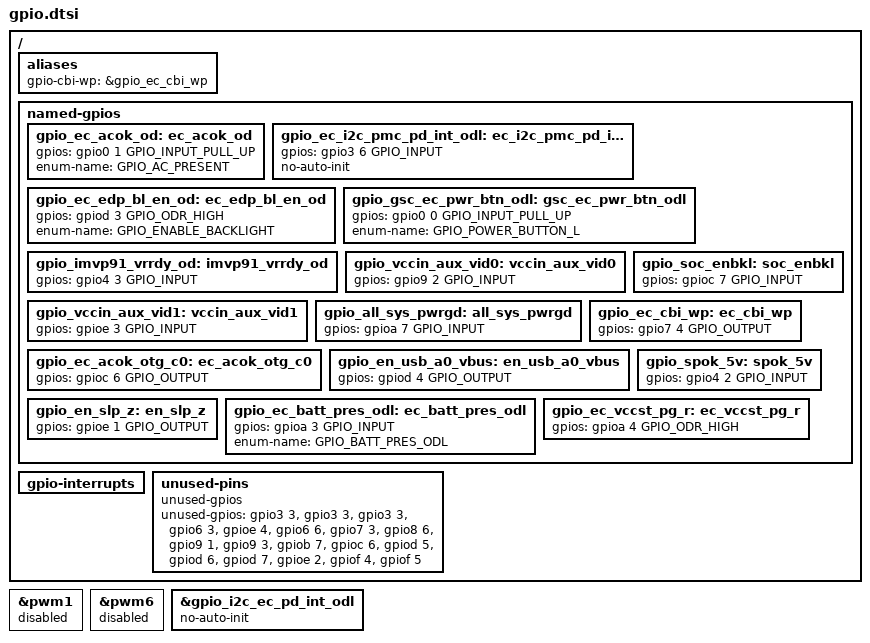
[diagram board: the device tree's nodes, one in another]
/* Copyright 2024 The ChromiumOS Authors
 * Use of this source code is governed by a BSD-style license that can be
 * found in the LICENSE file.
 */

 / {
	aliases {
		gpio-cbi-wp = &gpio_ec_cbi_wp;
	};

	named-gpios {
		/delete-node/ acok_od;
		/delete-node/ amp_mute_l;
		/delete-node/ charger_vap_otg_en;
		/delete-node/ ec_pmc_pd_int_odl;
		/delete-node/ ec_pwr_btn_odl;
		/delete-node/ ec_tris_l;
		/delete-node/ en_kb_bl;
		/delete-node/ en_pp5000_pen_x;
		/delete-node/ gsc_ec_pwr_btn_odl;
		/delete-node/ imvp91_vrrdy_r_od;
		/delete-node/ pdc_rst;
		/delete-node/ pen_detect_odl;
		/delete-node/ vccin_aux_r_vid0;
		/delete-node/ vccin_aux_r_vid1;
		/delete-node/ all_sys_pwrgd;
		/delete-node/ volup_btn_odl;
		/delete-node/ voldn_btn_odl;
		/delete-node/ en_pp5000_vbus;
		/delete-node/ ec_soc_vccst_pwrgd_od;
		/delete-node/ pg_pp5000_z1_od;

		gpio_ec_acok_od: ec_acok_od {
			gpios = <&gpio0 1 GPIO_INPUT_PULL_UP>;
			enum-name = "GPIO_AC_PRESENT";
		};
		gpio_ec_i2c_pmc_pd_int_odl: ec_i2c_pmc_pd_int_odl {
			gpios = <&gpio3 6 GPIO_INPUT>;
		};
		gpio_ec_edp_bl_en_od: ec_edp_bl_en_od {
			gpios = <&gpiod 3 GPIO_ODR_HIGH>;
			enum-name = "GPIO_ENABLE_BACKLIGHT";
		};
		gpio_gsc_ec_pwr_btn_odl: gsc_ec_pwr_btn_odl {
			gpios = <&gpio0 0 GPIO_INPUT_PULL_UP>;
			enum-name = "GPIO_POWER_BUTTON_L";
		};
		gpio_imvp91_vrrdy_od: imvp91_vrrdy_od {
			gpios = <&gpio4 3 GPIO_INPUT>;
		};
		gpio_vccin_aux_vid0: vccin_aux_vid0 {
			gpios = <&gpio9 2 GPIO_INPUT>;
		};
		gpio_vccin_aux_vid1: vccin_aux_vid1 {
			gpios = <&gpioe 3 GPIO_INPUT>;
		};
		gpio_all_sys_pwrgd: all_sys_pwrgd {
			gpios = <&gpioa 7 GPIO_INPUT>;
		};
		gpio_ec_acok_otg_c0: ec_acok_otg_c0 {
			gpios = <&gpioc 6 GPIO_OUTPUT>;
		};
		gpio_soc_enbkl: soc_enbkl {
			gpios = <&gpioc 7 GPIO_INPUT>;
		};
		gpio_ec_cbi_wp: ec_cbi_wp {
			gpios = <&gpio7 4 GPIO_OUTPUT>;
		};
		gpio_en_usb_a0_vbus: en_usb_a0_vbus {
			gpios = <&gpiod 4 GPIO_OUTPUT>;
		};
		gpio_spok_5v: spok_5v {
			gpios = <&gpio4 2 GPIO_INPUT>;
		};
		gpio_en_slp_z: en_slp_z {
			gpios = <&gpioe 1 GPIO_OUTPUT>;
		};
		gpio_ec_batt_pres_odl: ec_batt_pres_odl {
			gpios = <&gpioa 3 GPIO_INPUT>;
			enum-name = "GPIO_BATT_PRES_ODL";
		};
		gpio_ec_vccst_pg_r: ec_vccst_pg_r {
			gpios = <&gpioa 4 GPIO_ODR_HIGH>;
		};
	};
	gpio-interrupts {
		/delete-node/ vol_down;
		/delete-node/ vol_up;
	};
	unused-pins {
		compatible = "unused-gpios";
		unused-gpios =
			<&gpio3 3 0>,
			<&gpio3 3 0>,
			<&gpio3 3 0>,
			<&gpio6 3 0>,
			<&gpioe 4 0>,
			<&gpio6 6 0>,
			<&gpio7 3 0>,
			<&gpio8 6 0>,
			<&gpio9 1 0>,
			<&gpio9 3 0>,
			<&gpiob 7 0>,
			<&gpioc 6 0>,
			<&gpiod 5 0>,
			<&gpiod 6 0>,
			<&gpiod 7 0>,
			<&gpioe 2 0>,
			<&gpiof 4 0>,
			<&gpiof 5 0>;
	};
};
&pwm1 {
	status = "disabled";
};

&pwm6 {
	status = "disabled";
};

/* These GPIOS are initialized by the PDC driver */
&gpio_i2c_ec_pd_int_odl {
	no-auto-init;
};
&gpio_ec_i2c_pmc_pd_int_odl {
	no-auto-init;
};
